# STM32L422 register map
File version: 1.0
CPU: CM4 r0p1, little endian, MPU, FPU, 4 interrupt priority bits
Registers are 32-bit, read-write, reset 0x0 unless marked. A register's access mark holds for its fields unless they carry their own. Offsets are from the block's base; [hi:lo] are bit positions; {n}, {i} and the like mark numbered series.

## RNG — Random number generator
Base 0x50060800
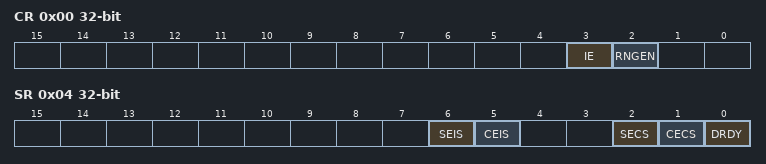
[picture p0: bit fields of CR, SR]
0x00 CR — control register
  [3] IE — Interrupt enable
  [2] RNGEN — Random number generator enable
0x04 SR access per field — status register
  [6] SEIS rw — Seed error interrupt status
  [5] CEIS rw — Clock error interrupt status
  [2] SECS ro — Seed error current status
  [1] CECS ro — Clock error current status
  [0] DRDY ro — Data ready
0x08 DR ro — data register
  [31:0] RNDATA — Random data

## SPI1 — Serial peripheral interface/Inter-IC sound
Base 0x40013000
Same registers: SPI2 0x40003800
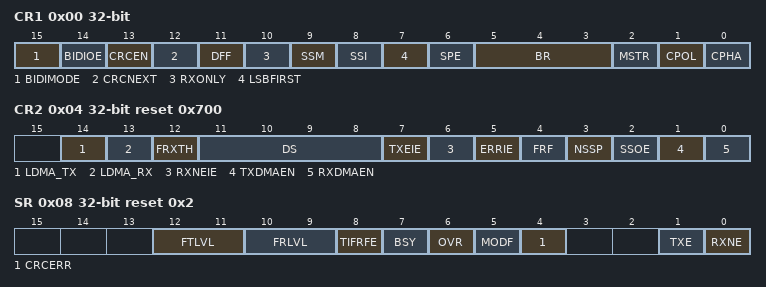
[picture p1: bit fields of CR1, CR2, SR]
0x00 CR1 — control register 1
  [15] BIDIMODE — Bidirectional data mode enable
  [14] BIDIOE — Output enable in bidirectional mode
  [13] CRCEN — Hardware CRC calculation enable
  [12] CRCNEXT — CRC transfer next
  [11] DFF — Data frame format
  [10] RXONLY — Receive only
  [9] SSM — Software slave management
  [8] SSI — Internal slave select
  [7] LSBFIRST — Frame format
  [6] SPE — SPI enable
  [5:3] BR — Baud rate control
  [2] MSTR — Master selection
  [1] CPOL — Clock polarity
  [0] CPHA — Clock phase
0x04 CR2 reset 0x700 — control register 2
  [14] LDMA_TX — Last DMA transfer for transmission
  [13] LDMA_RX — Last DMA transfer for reception
  [12] FRXTH — FIFO reception threshold
  [11:8] DS — Data size
  [7] TXEIE — Tx buffer empty interrupt enable
  [6] RXNEIE — RX buffer not empty interrupt enable
  [5] ERRIE — Error interrupt enable
  [4] FRF — Frame format
  [3] NSSP — NSS pulse management
  [2] SSOE — SS output enable
  [1] TXDMAEN — Tx buffer DMA enable
  [0] RXDMAEN — Rx buffer DMA enable
0x08 SR access per field reset 0x2 — status register
  [12:11] FTLVL ro — FIFO transmission level
  [10:9] FRLVL ro — FIFO reception level
  [8] TIFRFE ro — TI frame format error
  [7] BSY ro — Busy flag
  [6] OVR ro — Overrun flag
  [5] MODF ro — Mode fault
  [4] CRCERR rw — CRC error flag
  [1] TXE ro — Transmit buffer empty
  [0] RXNE ro — Receive buffer not empty
0x0C DR — data register
  [15:0] DR — Data register
0x10 CRCPR reset 0x7 — CRC polynomial register
  [15:0] CRCPOLY
0x14 RXCRCR ro — RX CRC register
  [15:0] RxCRC
0x18 TXCRCR ro — TX CRC register
  [15:0] TxCRC

## SYSCFG — System configuration controller
Base 0x40010000
0x00 MEMRMP — memory remap register
  [2:0] MEM_MODE — Memory mapping selection
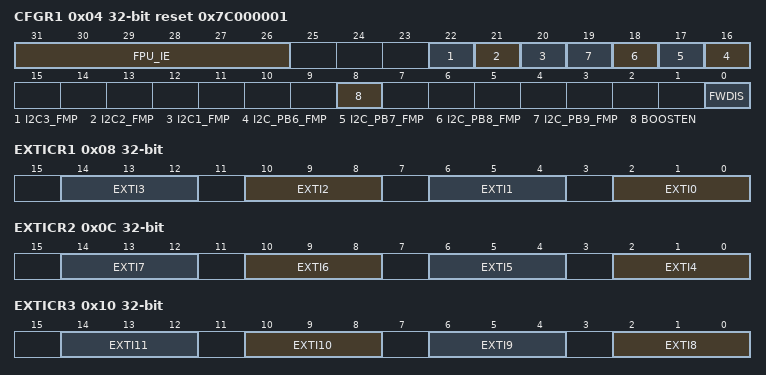
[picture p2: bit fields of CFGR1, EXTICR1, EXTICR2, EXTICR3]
0x04 CFGR1 reset 0x7C000001 — configuration register 1
  [31:26] FPU_IE — Floating Point Unit interrupts enable bits
  [22] I2C3_FMP — I2C3 Fast-mode Plus driving capability activation
  [21] I2C2_FMP — I2C2 Fast-mode Plus driving capability activation
  [20] I2C1_FMP — I2C1 Fast-mode Plus driving capability activation
  [n+10] I2C_PB{n}_FMP (n=6..9) — Fast-mode Plus (Fm+) driving capability activation on PB{n}
  [8] BOOSTEN — I/O analog switch voltage booster enable
  [0] FWDIS — Firewall disable
0x08 EXTICR1 — external interrupt configuration register 1
  [4n+2:4n] EXTI{n} (n=0..3) — EXTI {n} configuration bits
0x0C EXTICR2 — external interrupt configuration register 2
  [4n-14:4n-16] EXTI{n} (n=4..7) — EXTI {n} configuration bits
0x10 EXTICR3 — external interrupt configuration register 3
  [4n-30:4n-32] EXTI{n} (n=8..11) — EXTI {n} configuration bits
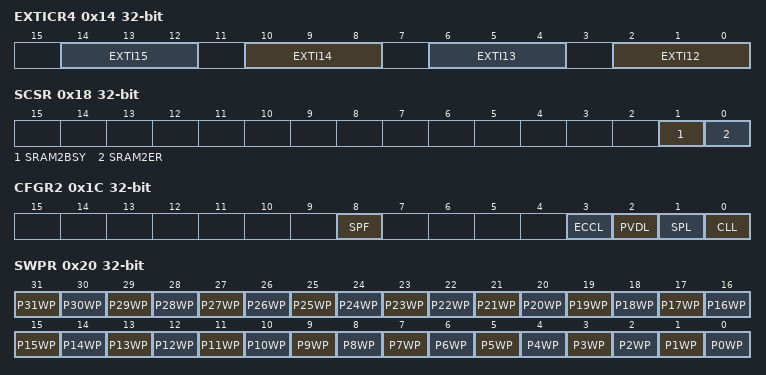
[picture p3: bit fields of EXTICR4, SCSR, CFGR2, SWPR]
0x14 EXTICR4 — external interrupt configuration register 4
  [4n-46:4n-48] EXTI{n} (n=12..15) — EXTI{n} configuration bits
0x18 SCSR access per field
  [1] SRAM2BSY ro — SRAM2 busy by erase operation
  [0] SRAM2ER rw — SRAM2 Erase
0x1C CFGR2 access per field
  [8] SPF rw — SRAM2 parity error flag
  [3] ECCL wo — ECC Lock
  [2] PVDL wo — PVD lock enable bit
  [1] SPL wo — SRAM2 parity lock bit
  [0] CLL wo — LOCKUP (Hardfault) output enable bit
0x20 SWPR wo
  [31] P31WP — SRAM2 page 31 write protection
  [n] P{n}WP (n=0..30)
0x24 SKR wo
  [7:0] KEY — SRAM2 write protection key for software erase

## Notices in the file
Copyright (c) 2024 STMicroelectronics.
SPDX-License-Identifier: Apache-2.0
Licensed under the Apache License, Version 2.0 (the "License");
you may not use this file except in compliance with the License.
You may obtain a copy of the License at
http://www.apache.org/licenses/LICENSE-2.0
Unless required by applicable law or agreed to in writing, software
distributed under the License is distributed on an "AS IS" BASIS,
WITHOUT WARRANTIES OR CONDITIONS OF ANY KIND, either express or implied.
See the License for the specific language governing permissions and
limitations under the License.
